VERSION "colliding-dbcs legacy 1.0"

NS_ :

BS_:

BU_: ECU1 GW

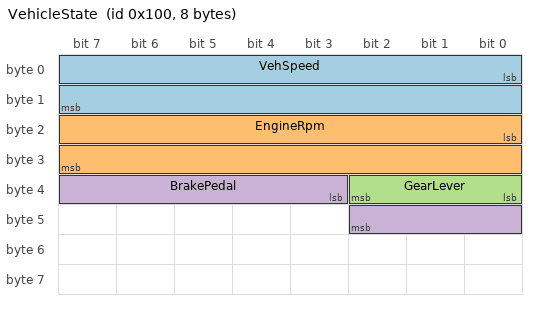
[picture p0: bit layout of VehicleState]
BO_ 256 VehicleState: 8 ECU1
 SG_ VehSpeed : 0|16@1+ (0.01,0) [0|655.35] "km/h" GW
 SG_ EngineRpm : 16|16@1+ (0.25,0) [0|16383.75] "rpm" GW
 SG_ GearLever : 32|3@1+ (1,0) [0|7] "" GW
 SG_ BrakePedal : 35|8@1+ (0.5,0) [0|127.5] "%" GW

BO_ 257 LegacyOnly: 4 ECU1
 SG_ LegacyHeartbeat : 0|8@1+ (1,0) [0|255] "" GW

CM_ BO_ 256 "The vehicle-state frame as the outgoing database defines it.";
CM_ SG_ 256 VehSpeed "Metric, and the same wire bits the replacement reads as mph.";

BA_DEF_ BO_ "GenMsgCycleTime" INT 0 100000;
BA_DEF_DEF_ "GenMsgCycleTime" 0;
BA_ "GenMsgCycleTime" BO_ 256 50;

VAL_ 256 GearLever 0 "P" 1 "R" 2 "N" 3 "D" 4 "S" 5 "L" 6 "Manual" 7 "Reserved";
